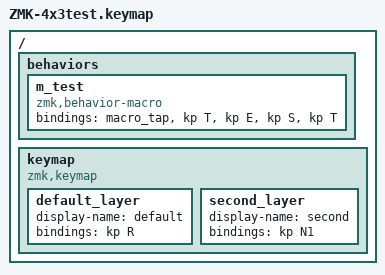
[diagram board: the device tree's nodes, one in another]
#include <behaviors.dtsi>
#include <dt-bindings/zmk/keys.h>
#include <dt-bindings/zmk/outputs.h>

/ {
    behaviors {
        m_test: m_test {
            compatible = "zmk,behavior-macro";
            #binding-cells = <0>;
            bindings
                = <&macro_tap &kp T &kp E &kp S &kp T> ;
        };
    };

    keymap {
        compatible = "zmk,keymap";

        default_layer {
            display-name = "default";
            bindings = <
                &kp R // &kp N2 &kp G
                // &kp T  &kp J  &kp C
                // &kp U  &kp G  &kp M
                // &kp I  &out OUT_TOG &to 1
            >;
        };
        second_layer {
            display-name = "second";
            bindings = <
                &kp N1 //&trans &kp N3
                // &kp N4 &kp N5 &kp N6
                // &kp N7 &kp N8 &kp N9
                // &m_test &trans &to 0
            >;
        };
    };
};
